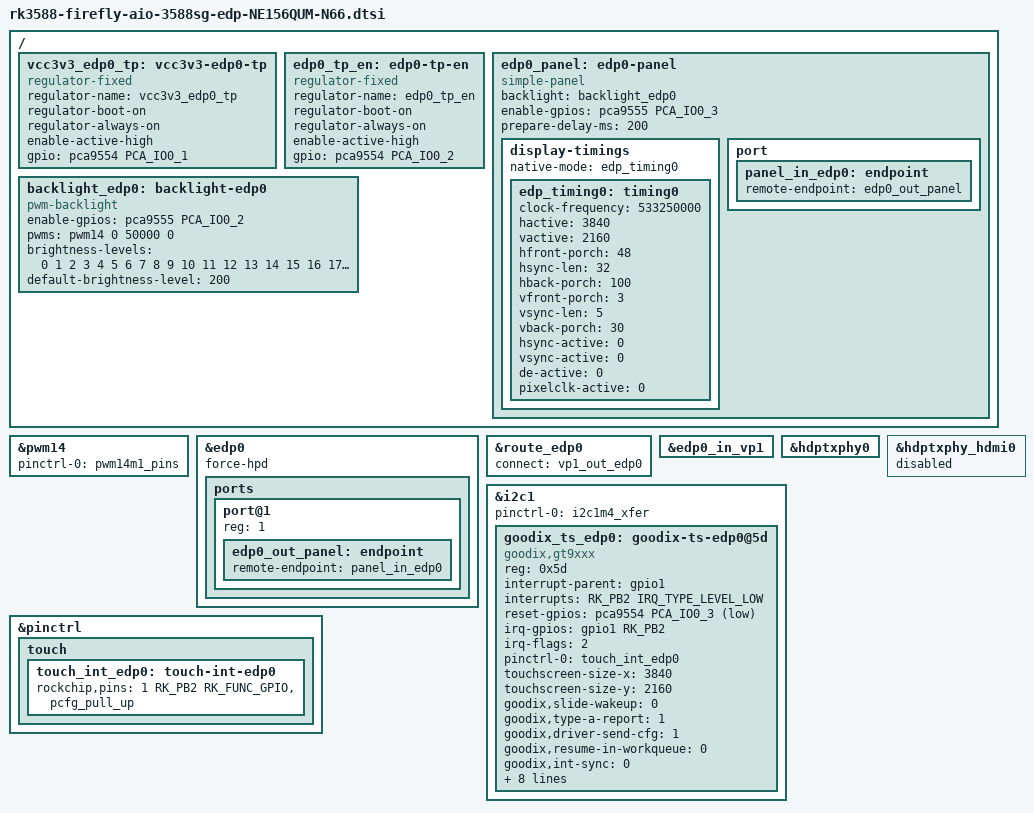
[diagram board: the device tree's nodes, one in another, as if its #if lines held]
// SPDX-License-Identifier: (GPL-2.0+ OR MIT)
/*
 * Copyright (c) 2023 Rockchip Electronics Co., Ltd.
 *
 */

/ {
#ifdef FF_BP
	vcc3v3_edp0_tp: vcc3v3-edp0-tp {
		status = "okay";
		compatible = "regulator-fixed";
		regulator-name = "vcc3v3_edp0_tp";
		regulator-boot-on;
		regulator-always-on;
		enable-active-high;
		gpio = <&pca9554 PCA_IO0_1 GPIO_ACTIVE_HIGH>;
	};

	edp0_tp_en: edp0-tp-en {
		status = "okay";
		compatible = "regulator-fixed";
		regulator-name = "edp0_tp_en";
		regulator-boot-on;
		regulator-always-on;
		enable-active-high;
		gpio = <&pca9554 PCA_IO0_2 GPIO_ACTIVE_HIGH>;
	};
#endif

	edp0_panel: edp0-panel {
		status = "okay";
		compatible = "simple-panel";
		backlight = <&backlight_edp0>;
		enable-gpios = <&pca9555 PCA_IO0_3 GPIO_ACTIVE_HIGH>;
		prepare-delay-ms = <200>;

		display-timings {
			native-mode = <&edp_timing0>;
			edp_timing0: timing0 {
				clock-frequency = <533250000>;  // Min 355.52 / Typ 533.25 / Max 586.6  (MHz)
				hactive = <3840>;
				vactive = <2160>;
				hfront-porch = <48>;
				hsync-len = <32>;
				hback-porch = <100>;
				vfront-porch = <3>;
				vsync-len = <5>;
				vback-porch = <30>;
				hsync-active = <0>;
				vsync-active = <0>;
				de-active = <0>;
				pixelclk-active = <0>;
			};
		};

		port {
			panel_in_edp0: endpoint {
				remote-endpoint = <&edp0_out_panel>;
			};
		};
	};

	backlight_edp0: backlight-edp0 {
		status = "okay";
		compatible = "pwm-backlight";
		enable-gpios = <&pca9555 PCA_IO0_2 GPIO_ACTIVE_HIGH>; // EDP_BL_EN
		pwms = <&pwm14 0 50000 0>;
		brightness-levels = <
			  0   1   2   3   4   5   6   7
			  8   9  10  11  12  13  14  15
			 16  17  18  19  20  21  22  23
			 24  25  26  27  28  29  30  31
			 32  33  34  35  36  37  38  39
			 40  41  42  43  44  45  46  47
			 48  49  50  51  52  53  54  55
			 56  57  58  59  60  61  62  63
			 64  65  66  67  68  69  70  71
			 72  73  74  75  76  77  78  79
			 80  81  82  83  84  85  86  87
			 88  89  90  91  92  93  94  95
			 96  97  98  99 100 101 102 103
			104 105 106 107 108 109 110 111
			112 113 114 115 116 117 118 119
			120 121 122 123 124 125 126 127
			128 129 130 131 132 133 134 135
			136 137 138 139 140 141 142 143
			144 145 146 147 148 149 150 151
			152 153 154 155 156 157 158 159
			160 161 162 163 164 165 166 167
			168 169 170 171 172 173 174 175
			176 177 178 179 180 181 182 183
			184 185 186 187 188 189 190 191
			192 193 194 195 196 197 198 199
			200 201 202 203 204 205 206 207
			208 209 210 211 212 213 214 215
			216 217 218 219 220 221 222 223
			224 225 226 227 228 229 230 231
			232 233 234 235 236 237 238 239
			240 241 242 243 244 245 246 247
			248 249 250 251 252 253 254 255 >;
		default-brightness-level = <200>;
	};
};

&pwm14 {
	status = "okay";
	pinctrl-0 = <&pwm14m1_pins>;
};

&edp0 {
	status = "okay";
	force-hpd;
	//hpd-gpios = <&gpio1 RK_PA6 GPIO_ACTIVE_HIGH>;

	ports {
		port@1 {
			reg = <1>;
			edp0_out_panel: endpoint {
				remote-endpoint = <&panel_in_edp0>;
			};
		};
	};
};

&route_edp0 {
	status = "okay";
	connect = <&vp1_out_edp0>;
};

&edp0_in_vp1 {
	status = "okay";
};

&hdptxphy0 {
	status = "okay";
};

&hdptxphy_hdmi0 {
	status = "disabled";
};

#ifdef FF_BP
&i2c1 {
	status = "okay";
	pinctrl-names = "default";
	pinctrl-0 = <&i2c1m4_xfer>;

	goodix_ts_edp0: goodix-ts-edp0@5d {
		status = "okay";
		compatible = "goodix,gt9xxx";
		reg = <0x5d>;
		interrupt-parent = <&gpio1>;
		interrupts = <RK_PB2 IRQ_TYPE_LEVEL_LOW>;
		reset-gpios = <&pca9554 PCA_IO0_3 GPIO_ACTIVE_LOW>;
		irq-gpios = <&gpio1 RK_PB2 IRQ_TYPE_EDGE_FALLING>;
		irq-flags = <2>; /* 1 rising, 2 falling */
		pinctrl-names = "default";
		pinctrl-0 = <&touch_int_edp0>;
		touchscreen-size-x = <3840>;
		touchscreen-size-y = <2160>;
		goodix,slide-wakeup = <0>;
		goodix,type-a-report = <1>;
		goodix,driver-send-cfg = <1>;
		goodix,resume-in-workqueue = <0>;
		goodix,int-sync = <0>;
		goodix,esd-protect = <0>;
		goodix,auto-update-cfg = <1>;
		goodix,auto-update = <0>;
		goodix,power-off-sleep = <0>;
		goodix,pen-suppress-finger = <0>;
		goodix,has-pen = <0>;

		goodix,cfg-group2 = [
			5a 00 40 80 25 0a 7d 00 01 08
			28 05 5f 32 03 05 00 00 00 00
			00 00 00 1a 1c 1e 14 95 35 ff
			2a 2c b5 06 00 00 02 b9 03 1d
			1a 1c 1e 90 00 00 00 00 00 00
			00 1e 42 94 c5 02 07 00 00 04
			f5 20 00 c7 26 00 a6 2c 00 8a
			34 00 73 3d 00 73 00 00 00 00
			00 00 00 00 00 00 00 00 00 00
			00 00 00 00 00 00 00 00 00 00
			00 00 00 00 03 00 00 00 00 00
			00 00 00 01 02 03 04 05 06 07
			08 09 0a 0b 0c 0d 0e 0f 10 11
			12 13 14 15 16 17 18 19 1a 1b
			1c 1d 2a 29 28 27 26 25 24 23
			22 21 20 1f 1e 1d 1c 1b 19 18
			17 16 15 14 13 12 11 10 0f 0e
			0d 0c 0b 0a 09 08 07 06 05 04
			03 02 01 00 cc 01];
	};
};

&pinctrl {
	touch {
		touch_int_edp0: touch-int-edp0 {
			rockchip,pins = <1 RK_PB2 RK_FUNC_GPIO &pcfg_pull_up>;
		};
	};
};
#endif
